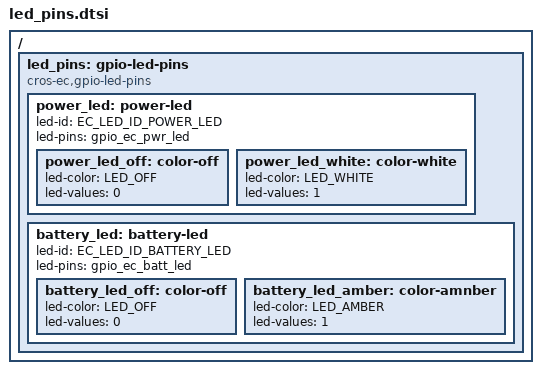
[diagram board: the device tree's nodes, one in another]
/* Copyright 2025 The ChromiumOS Authors
 * Use of this source code is governed by a BSD-style license that can be
 * found in the LICENSE file.
 */

 / {
	led_pins: gpio-led-pins {
		compatible = "cros-ec,gpio-led-pins";

		power_led: power-led {
			led-id = "EC_LED_ID_POWER_LED";
			led-pins = <&gpio_ec_pwr_led>;

			power_led_off: color-off {
				led-color = "LED_OFF";
				led-values = <0>;
			};

			power_led_white: color-white {
				led-color = "LED_WHITE";
				led-values = <1>;
			};
		};

		battery_led: battery-led {
			led-id = "EC_LED_ID_BATTERY_LED";
			led-pins = <&gpio_ec_batt_led>;

			battery_led_off: color-off {
				led-color = "LED_OFF";
				led-values = <0>;
			};

			battery_led_amber: color-amnber {
				led-color = "LED_AMBER";
				led-values = <1>;
			};
		};
	};
};
